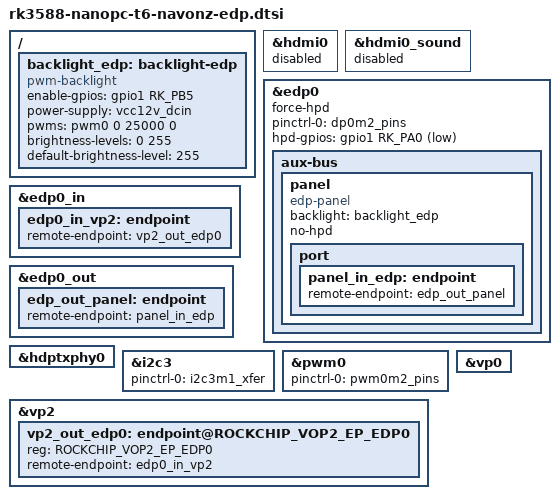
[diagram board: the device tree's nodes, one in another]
// SPDX-License-Identifier: (GPL-2.0+ OR MIT)
/*
 * Navonz RK3588 carrier + Sharp LQ134R1JW52 eDP panel overlay
 *
 * Physical interconnect (RK3588 board + BMS display board, independently wired):
 *   Video:  J7 (TX0 combo PHY) -- LCD cable --> BMS host LCD input.
 *           Firmware selects edp0 on hdptxphy0; J7 is an HDMI-type connector
 *           but lane signaling is eDP, not TMDS (hdmi0 stays disabled).
 *   Control: J13 (RK3588) -- ribbon 2x20 --> J17 (BMS); no video on J17:
 *   HPD:        GPIO1_A0 via DP0_HPDIN_M2 (active-low, 0 = panel present)
 *   BL enable:  GPIO1_B5 (HOST_LCD_BL_ENABLE)
 *   BL PWM:     PWM0_M2 on GPIO1_A2
 *   Touch I2C:  I2C3_M1 (GPIO3_B7 / GPIO3_C0) — device node deferred until i2cdetect
 *
 * Display pipeline: disable HDMI TX0, route VP2 -> eDP0 (hdptxphy0 / TX0 -> J7).
 * HDMI TX1 (J15) remains available for external monitor.
 */

/ {
	/delete-node/ hdmi0-con;

	backlight_edp: backlight-edp {
		compatible = "pwm-backlight";
		enable-gpios = <&gpio1 RK_PB5 GPIO_ACTIVE_HIGH>;
		power-supply = <&vcc12v_dcin>;
		pwms = <&pwm0 0 25000 0>;
		brightness-levels = <0 255>;
		default-brightness-level = <255>;
	};
};

&hdmi0 {
	status = "disabled";
};

&hdmi0_sound {
	status = "disabled";
};

/delete-node/ &hdmi0_in;
/delete-node/ &hdmi0_out;

&edp0 {
	force-hpd;
	status = "okay";
	pinctrl-names = "default";
	pinctrl-0 = <&dp0m2_pins>;
	hpd-gpios = <&gpio1 RK_PA0 GPIO_ACTIVE_LOW>;

	aux-bus {
		panel {
			compatible = "edp-panel";
			backlight = <&backlight_edp>;
			no-hpd;

			port {
				panel_in_edp: endpoint {
					remote-endpoint = <&edp_out_panel>;
				};
			};
		};
	};
};

&edp0_in {
	edp0_in_vp2: endpoint {
		remote-endpoint = <&vp2_out_edp0>;
	};
};

&edp0_out {
	edp_out_panel: endpoint {
		remote-endpoint = <&panel_in_edp>;
	};
};

&hdptxphy0 {
	status = "okay";
};

&i2c3 {
	pinctrl-names = "default";
	pinctrl-0 = <&i2c3m1_xfer>;
	status = "okay";
};

&pwm0 {
	pinctrl-0 = <&pwm0m2_pins>;
	status = "okay";
};

&vp0 {
	/delete-node/ endpoint@ROCKCHIP_VOP2_EP_HDMI0;
};

&vp2 {
	vp2_out_edp0: endpoint@ROCKCHIP_VOP2_EP_EDP0 {
		reg = <ROCKCHIP_VOP2_EP_EDP0>;
		remote-endpoint = <&edp0_in_vp2>;
	};
};
